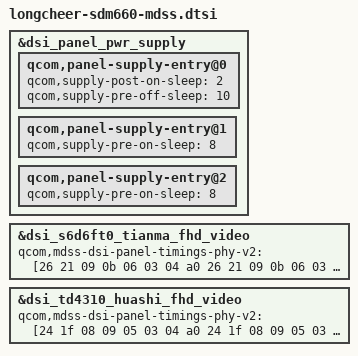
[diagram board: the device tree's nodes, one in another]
/* Copyright (c) 2019, The Linux Foundation. All rights reserved.
 *
 * This program is free software; you can redistribute it and/or modify
 * it under the terms of the GNU General Public License version 2 and
 * only version 2 as published by the Free Software Foundation.
 *
 * This program is distributed in the hope that it will be useful,
 * but WITHOUT ANY WARRANTY; without even the implied warranty of
 * MERCHANTABILITY or FITNESS FOR A PARTICULAR PURPOSE.  See the
 * GNU General Public License for more details.
 */
#include "display/dsi-panel-tianma-s6d6ft0-1080p-video.dtsi"
#include "display/dsi-panel-huashi-td4310-1080p-video.dtsi"

/* sdm660-mdss-panels.dtsi common diff */
&dsi_panel_pwr_supply {
	qcom,panel-supply-entry@0 {
		qcom,supply-post-on-sleep = <2>;
		qcom,supply-pre-off-sleep = <10>;
	};

	qcom,panel-supply-entry@1 {
		qcom,supply-pre-on-sleep = <8>;
	};

	qcom,panel-supply-entry@2 {
		qcom,supply-pre-on-sleep = <8>;
	};
};

&dsi_s6d6ft0_tianma_fhd_video {
	qcom,mdss-dsi-panel-timings-phy-v2 = [26 21 09 0b 06 03 04 a0
		26 21 09 0b 06 03 04 a0
		26 21 09 0b 06 03 04 a0
		26 21 09 0b 06 03 04 a0
		26 20 09 0a 06 03 04 a0];
};

 &dsi_td4310_huashi_fhd_video {
	qcom,mdss-dsi-panel-timings-phy-v2 = [24 1f 08 09 05 03 04 a0
		24 1f 08 09 05 03 04 a0
		24 1f 08 09 05 03 04 a0
		24 1f 08 09 05 03 04 a0
		24 1f 08 09 05 03 04 a0];
};
